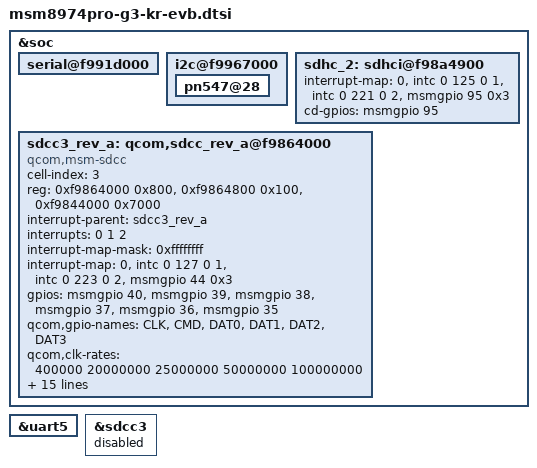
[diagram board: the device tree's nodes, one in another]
/* Copyright (c) 2012, Code Aurora Forum. All rights reserved.
 *
 * This program is free software; you can redistribute it and/or modify
 * it under the terms of the GNU General Public License version 2 and
 * only version 2 as published by the Free Software Foundation.
 *
 * This program is distributed in the hope that it will be useful,
 * but WITHOUT ANY WARRANTY; without even the implied warranty of
 * MERCHANTABILITY or FITNESS FOR A PARTICULAR PURPOSE.  See the
 * GNU General Public License for more details.
 */

/include/ "msm8974pro-g3-kr-evb-panel.dtsi"
/include/ "msm8974pro-g3-kr-evb-input.dtsi"
/include/ "msm8974pro-g3-kr-evb-hdmi.dtsi"
/include/ "msm8974pro-g3-kr-evb-usb.dtsi"
/include/ "msm8974pro-g3-kr-evb-misc.dtsi"
/include/ "msm8974pro-g3-kr-evb-pm.dtsi"
/include/ "msm8974pro-g3-kr-evb-camera.dtsi"
/include/ "msm8974pro-g3-kr-evb-sound.dtsi"
/include/ "msm8974pro-g3-kr-evb-nfc.dtsi" /* [NFC][seunghoon65.lee@lge.com], B2 Bring up */

&soc {
	serial@f991d000 {
	        status = "ok";
	};
	/*  LGE_CHANGE_S, [NFC][seunghoon65.lee@lge.com], B2 Bring up */	
	i2c@f9967000 {
		pn547@28 {
			status = "ok";
		};
	};
	/*  LGE_CHANGE_E, [NFC][seunghoon65.lee@lge.com], B2 Bring up */

	sdhc_2: sdhci@f98a4900 {
		interrupt-map = <0 &intc 0 125 0
			1 &intc 0 221 0
			2 &msmgpio 95 0x3>;
		cd-gpios = <&msmgpio 95 0x0>;
	};

};
&uart5 {
	status = "ok";
};

/* LGE_CHANGE_S, [WiFi][jaewoo.hwang@lge.com], 2013-01-28, Wifi Bring Up */
&soc {
	sdcc3_rev_a: qcom,sdcc_rev_a@f9864000 {
		cell-index = <3>; /* SDC3 WLAN slot */
		compatible = "qcom,msm-sdcc";
		reg = <0xf9864000 0x800>,
			<0xf9864800 0x100>,
			<0xf9844000 0x7000>;
		reg-names = "core_mem", "dml_mem", "bam_mem";
		#address-cells = <0>;
		interrupt-parent = <&sdcc3_rev_a>;
		interrupts = <0 1 2>;
		#interrupt-cells = <1>;
		interrupt-map-mask = <0xffffffff>;
		interrupt-map = <0 &intc 0 127 0
				1 &intc 0 223 0
				2 &msmgpio 44 0x3>;
		interrupt-names = "core_irq", "bam_irq", "wlan_oob_irq";

		gpios = <&msmgpio 40 0>, /* CLK */
			<&msmgpio 39 0>, /* CMD */
			<&msmgpio 38 0>, /* DATA0 */
			<&msmgpio 37 0>, /* DATA1 */
			<&msmgpio 36 0>, /* DATA2 */
			<&msmgpio 35 0>; /* DATA3 */
		qcom,gpio-names = "CLK", "CMD", "DAT0", "DAT1", "DAT2", "DAT3";

		qcom,clk-rates = <400000 20000000 25000000 50000000 100000000>;
		qcom,sup-voltages = <1800 2950>;
		qcom,bus-width = <4>;
		qcom,nonremovable;
		qcom,bus-speed-mode = "SDR12", "SDR25", "SDR50";

		qcom,msm-bus,name = "sdcc3";
		qcom,msm-bus,num-cases = <8>;
		qcom,msm-bus,active-only = <0>;
		qcom,msm-bus,num-paths = <1>;
		qcom,msm-bus,vectors-KBps = <79 512 0 0>, /* No vote */
				<79 512 1600 3200>,    /* 400 KB/s*/
				<79 512 80000 160000>, /* 20 MB/s */
				<79 512 100000 200000>, /* 25 MB/s */
				<79 512 200000 400000>, /* 50 MB/s */
				<79 512 400000 800000>, /* 100 MB/s */
				<79 512 800000 1600000>, /* 200 MB/s */
				<79 512 2048000 4096000>; /* Max. bandwidth */
		qcom,bus-bw-vectors-bps = <0 400000 20000000 25000000 50000000 100000000 200000000 4294967295>;
		status = "ok";
	};

	
};


&sdcc3 {
	status = "disable";
};
/* LGE_CHANGE_E, [WiFi][jaewoo.hwang@lge.com], 2013-01-28, Wifi Bring Up */
